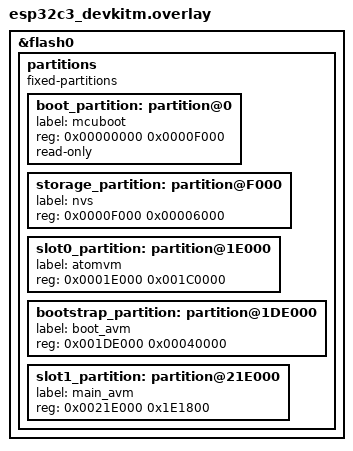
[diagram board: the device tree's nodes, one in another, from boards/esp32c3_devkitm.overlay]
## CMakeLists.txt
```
#
# This file is part of AtomVM.
#
# Copyright 2023 Winford (Uncle Grumpy) <winford@object.stream>
#
# Licensed under the Apache License, Version 2.0 (the "License");
# you may not use this file except in compliance with the License.
# You may obtain a copy of the License at
#
#    http://www.apache.org/licenses/LICENSE-2.0
#
# Unless required by applicable law or agreed to in writing, software
# distributed under the License is distributed on an "AS IS" BASIS,
# WITHOUT WARRANTIES OR CONDITIONS OF ANY KIND, either express or implied.
# See the License for the specific language governing permissions and
# limitations under the License.
#
# SPDX-License-Identifier: Apache-2.0 OR LGPL-2.1-or-later
#

cmake_minimum_required (VERSION 3.13)
set(CMAKE_C_STANDARD_REQUIRED YES)
set(CMAKE_CXX_STANDARD_REQUIRED YES)
# Enforce to disable any compiler-specific extensions
set(CMAKE_C_EXTENSIONS NO)
set(CMAKE_CXX_EXTENSIONS NO)
list(APPEND CMAKE_MODULE_PATH "${CMAKE_CURRENT_SOURCE_DIR}/../../../CMakeModules")

if (NOT BOARD)
    message(FATAL_ERROR "No BOARD specified for device config generator")
endif ()

find_package(Zephyr REQUIRED HINTS $ENV{ZEPHYR_BASE})
set(AVM_ZEPHYR_BUILD ON)
set_property(GLOBAL PROPERTY AVM_ZEPHYR_BUILD ON)
set_property(TARGET app PROPERTY CSTD 11)
set_property(GLOBAL PROPERTY CSTD c11)

project(AtomVM LANGUAGES C)

set(AVM_PEDANTIC_WARNINGS OFF)

if (CONFIG_ATOMVM_DISABLE_SMP)
    set(CMAKE_C_FLAGS "${CMAKE_C_FLAGS} -DAVM_NO_SMP")
endif()

if (CONFIG_AVM_CREATE_STACKTRACES)
    set(AVM_CREATE_STACKTRACES on)
endif()

if (CONFIG_AVM_USE_32BIT_FLOAT)
    set(AVM_USE_32BIT_FLOAT on)
endif()

if (CONFIG_AVM_VERBOSE_ABORT)
    set(AVM_VERBOSE_ABORT on)
endif()

if (CONFIG_REBOOT_ON_NOT_OK)
    add_compile_definitions(CONFIG_REBOOT_ON_NOT_OK)
endif()

    # Configure logging
if (CONFIG_AVM_LOG_DISABLE)
    add_compile_definitions(AVM_LOG_DISABLE)
elseif (CONFIG_AVM_LOG_LEVEL_MAX)
    set(AVM_LOG_LEVEL_MAX ${CONFIG_AVM_LOG_LEVEL_MAX} CACHE STRING "AtomVM max log level")
elseif (CONFIG_LOG_NONE)
    add_compile_definitions(AVM_LOG_DISABLE)
elseif (CONFIG_LOG_ERROR)
    set(AVM_LOG_LEVEL_MAX LOG_ERROR CACHE STRING "AtomVM max log level")
elseif (CONFIG_LOG_WARN)
    set(AVM_LOG_LEVEL_MAX LOG_WARN CACHE STRING "AtomVM max log level")
elseif (CONFIG_LOG_INFO)
    set(AVM_LOG_LEVEL_MAX LOG_INFO CACHE STRING "AtomVM max log level")
elseif (CONFIG_LOG_DEBUG)
    set(AVM_LOG_LEVEL_MAX LOG_DEBUG CACHE STRING "AtomVM max log level")
else()
    set(AVM_LOG_LEVEL_MAX LOG_INFO CACHE STRING "AtomVM max log level")
endif()
if (AVM_LOG_LEVEL_MAX)
    set_property(CACHE AVM_LOG_LEVEL_MAX PROPERTY STRINGS LOG_NONE LOG_ERROR LOG_WARN LOG_INFO LOG_DEBUG)
    add_compile_definitions(AVM_LOG_LEVEL_MAX=${AVM_LOG_LEVEL_MAX})
endif()
if (CONFIG_AVM_ENABLE_LOG_COLOR)
    add_compile_definitions(ENABLE_LOG_COLOR)
endif()
if (CONFIG_AVM_ENABLE_LOG_LINES)
    add_compile_definitions(ENABLE_LOG_LINE_INFO)
endif()

set(
    PLATFORM_LIB_SUFFIX
    ${CMAKE_SYSTEM_NAME}-${CMAKE_SYSTEM_PROCESSOR}
)

# Specify output executable
target_sources(app PRIVATE src/main.c)
target_include_directories(app PRIVATE
    ${CMAKE_CURRENT_SOURCE_DIR}/src/lib
    ${CMAKE_CURRENT_BINARY_DIR}/libAtomVM
    ${CMAKE_CURRENT_SOURCE_DIR}/../../libAtomVM
    ${CMAKE_BINARY_DIR}/zephyr/include/generated
)

add_subdirectory(${CMAKE_CURRENT_SOURCE_DIR}/../../libAtomVM libAtomVM)
target_link_libraries(app PUBLIC libAtomVM)

add_subdirectory(src/lib)
target_link_libraries(app PUBLIC libAtomVM${PLATFORM_LIB_SUFFIX})

if(CMAKE_COMPILER_IS_GNUCC)
    target_compile_options(app PUBLIC -Wall -Wextra -ggdb)
endif()

message("----------------------------------------")
message(STATUS "System name  : ${CMAKE_SYSTEM_NAME}")
message(STATUS "Board        : ${BOARD}")
message(STATUS "Processor    : ${CMAKE_SYSTEM_PROCESSOR}")
message(STATUS "CPU cores    : ${CONFIG_MP_MAX_NUM_CPUS}")
message("--------Device Configuration Info-------")
message(STATUS "Clock Hz     : ${CONFIG_SYS_CLOCK_HW_CYCLES_PER_SEC}")
if (CONFIG_FLASH_SIZE)
message(STATUS "Flash Size   : ${CONFIG_FLASH_SIZE} KiB")
endif()
message("---------Build Configuration------------")
message(STATUS "Zephyr build : ${AVM_ZEPHYR_BUILD}")
message(STATUS "Log Level    : ${AVM_LOG_LEVEL_MAX}")
message(STATUS "Color Logs   : ${CONFIG_AVM_ENABLE_LOG_COLOR}")
message(STATUS "Log all lines: ${CONFIG_AVM_ENABLE_LOG_LINES}")
message(STATUS "Stactraces   : ${CONFIG_AVM_CREATE_STACKTRACES}")
message(STATUS "Verbose abort: ${CONFIG_AVM_VERBOSE_ABORT}")
message(STATUS "Error Reboot : ${CONFIG_REBOOT_ON_NOT_OK}")
message(STATUS "SMP disabled : ${CONFIG_ATOMVM_DISABLE_SMP}")
message(STATUS "32-Bit Floats: ${AVM_USE_32BIT_FLOAT}")
message(STATUS "Sim Flash    : ${CONFIG_FLASH_SIMULATOR}")
```

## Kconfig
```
#
# This file is part of AtomVM.
#
# Copyright 2023 Adolfo E. García 
# Copyright 2023 Winford (Uncle Grumpy) <winford@object.stream>
#
# Licensed under the Apache License, Version 2.0 (the "License");
# you may not use this file except in compliance with the License.
# You may obtain a copy of the License at
#
#    http://www.apache.org/licenses/LICENSE-2.0
#
# Unless required by applicable law or agreed to in writing, software
# distributed under the License is distributed on an "AS IS" BASIS,
# WITHOUT WARRANTIES OR CONDITIONS OF ANY KIND, either express or implied.
# See the License for the specific language governing permissions and
# limitations under the License.
#
# SPDX-License-Identifier: Apache-2.0 OR LGPL-2.1-or-later

rsource "$ZEPHYR_BASE/Kconfig"

menu "AtomVM"
config ATOMVM
    bool "AtomVM"
    default y
    help
        Enables the AtomVM Module
    select CBPRINTF_PACKAGE_LONGDOUBLE
    select CONSOLE_SUBSYS
    select EMIT_ALL_SYSCALLS
    select FLASH
    select FLASH_MAP
    select FLASH_MAP_CUSTOM
    select FLASH_MAP_LABELS
    select HAVE_CLOCK_SETTIME
    select OUTPUT_PRINT_MEMORY_USAGE
    select REQUIRES_FLOAT_PRINTF
    select RTC
    select STACK_USAGE
    select UTF8

    if ATOMVM
    rsource "src/Kconfig"
    endif

if ATOMVM

module = ATOMVM
module-str = AtomVM

endif

endmenu
```

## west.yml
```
# Copyright (c) 2021 Nordic Semiconductor ASA
# SPDX-License-Identifier: Apache-2.0

manifest:
  remotes:
    - name: zephyrproject-rtos
      url-base: https://github.com/zephyrproject-rtos
  defaults:
    remote: zephyrproject-rtos
  projects:
    - name: zephyr
      remote: zephyrproject-rtos
      revision: v3.5.0
      import:
        # By using name-allowlist we can clone only the modules that are
        # strictly needed by the application.
        name-allowlist:
          - cmsis          # required by the ARM port
          - stm32          # required by STM32 boards
          - native_sim_64  # 64-bit native
          - qemu_x86_64    # QEMU 64-bit virtual machine
  self:
    path: .
```

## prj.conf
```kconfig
#
# This file is part of AtomVM.
#
# Copyright 2023 Winford (Uncle Grumpy) <winford@object.stream>
#
# Licensed under the Apache License, Version 2.0 (the "License");
# you may not use this file except in compliance with the License.
# You may obtain a copy of the License at
#
#    http://www.apache.org/licenses/LICENSE-2.0
#
# Unless required by applicable law or agreed to in writing, software
# distributed under the License is distributed on an "AS IS" BASIS,
# WITHOUT WARRANTIES OR CONDITIONS OF ANY KIND, either express or implied.
# See the License for the specific language governing permissions and
# limitations under the License.
#
# SPDX-License-Identifier: Apache-2.0 OR LGPL-2.1-or-later
#

CONFIG_KERNEL_BIN_NAME="AtomVM"
CONFIG_RUNTIME_ERROR_CHECKS=y
CONFIG_FORTIFY_SOURCE_RUN_TIME=y
CONFIG_FLASH=y
CONFIG_SPI=y


CONFIG_STDOUT_CONSOLE=y
CONFIG_CONSOLE_SUBSYS=y
CONFIG_POSIX_API=y
CONFIG_APP_LINK_WITH_POSIX_SUBSYS=y
CONFIG_POSIX_CLOCK=y
CONFIG_FPU=y
CONFIG_FP_HARDABI=y
CONFIG_GPIO=y
CONFIG_PINCTRL_DYNAMIC=y
CONFIG_DYNAMIC_INTERRUPTS=y
CONFIG_RESET=y
CONFIG_REBOOT=y
CONFIG_PICOLIBC=y


# CONFIG_DEBUG_OPTIMIZATIONS=y

CONFIG_APPLICATION_DEFINED_SYSCALL=y
CONFIG_EMIT_ALL_SYSCALLS=y
```

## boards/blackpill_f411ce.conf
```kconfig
#
# This file is part of AtomVM.
#
# Copyright 2023 Winford (Uncle Grumpy) <winford@object.stream>
#
# Licensed under the Apache License, Version 2.0 (the "License");
# you may not use this file except in compliance with the License.
# You may obtain a copy of the License at
#
#    http://www.apache.org/licenses/LICENSE-2.0
#
# Unless required by applicable law or agreed to in writing, software
# distributed under the License is distributed on an "AS IS" BASIS,
# WITHOUT WARRANTIES OR CONDITIONS OF ANY KIND, either express or implied.
# See the License for the specific language governing permissions and
# limitations under the License.
#
# SPDX-License-Identifier: Apache-2.0 OR LGPL-2.1-or-later
#

CONFIG_STDOUT_CONSOLE=y
CONFIG_POSIX_API=y
CONFIG_POSIX_CLOCK=y
```

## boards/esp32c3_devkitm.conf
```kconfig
#
# This file is part of AtomVM.
#
# Copyright 2023 Winford (Uncle Grumpy) <winford@object.stream>
#
# Licensed under the Apache License, Version 2.0 (the "License");
# you may not use this file except in compliance with the License.
# You may obtain a copy of the License at
#
#    http://www.apache.org/licenses/LICENSE-2.0
#
# Unless required by applicable law or agreed to in writing, software
# distributed under the License is distributed on an "AS IS" BASIS,
# WITHOUT WARRANTIES OR CONDITIONS OF ANY KIND, either express or implied.
# See the License for the specific language governing permissions and
# limitations under the License.
#
# SPDX-License-Identifier: Apache-2.0 OR LGPL-2.1-or-later
#

CONFIG_FPU=n
CONFIG_POSIX_CLOCK=y
```

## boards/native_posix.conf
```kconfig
#
# This file is part of AtomVM.
#
# Copyright 2023 Winford (Uncle Grumpy) <winford@object.stream>
#
# Licensed under the Apache License, Version 2.0 (the "License");
# you may not use this file except in compliance with the License.
# You may obtain a copy of the License at
#
#    http://www.apache.org/licenses/LICENSE-2.0
#
# Unless required by applicable law or agreed to in writing, software
# distributed under the License is distributed on an "AS IS" BASIS,
# WITHOUT WARRANTIES OR CONDITIONS OF ANY KIND, either express or implied.
# See the License for the specific language governing permissions and
# limitations under the License.
#
# SPDX-License-Identifier: Apache-2.0 OR LGPL-2.1-or-later
#

CONFIG_KERNEL_BIN_NAME="AtomVM"
CONFIG_ATOMVM_DISABLE_SMP=y
CONFIG_FLASH_SIMULATOR=y

CONFIG_RESET=n
CONFIG_REBOOT=n

CONFIG_RUNTIME_ERROR_CHECKS=y
CONFIG_FORTIFY_SOURCE_RUN_TIME=y
CONFIG_DEBUG_OPTIMIZATIONS=y
```

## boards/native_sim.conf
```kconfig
#
# This file is part of AtomVM.
#
# Copyright 2023 Winford (Uncle Grumpy) <winford@object.stream>
#
# Licensed under the Apache License, Version 2.0 (the "License");
# you may not use this file except in compliance with the License.
# You may obtain a copy of the License at
#
#    http://www.apache.org/licenses/LICENSE-2.0
#
# Unless required by applicable law or agreed to in writing, software
# distributed under the License is distributed on an "AS IS" BASIS,
# WITHOUT WARRANTIES OR CONDITIONS OF ANY KIND, either express or implied.
# See the License for the specific language governing permissions and
# limitations under the License.
#
# SPDX-License-Identifier: Apache-2.0 OR LGPL-2.1-or-later
#

CONFIG_KERNEL_BIN_NAME="AtomVM"
CONFIG_ATOMVM_DISABLE_SMP=y
CONFIG_FLASH_SIMULATOR=y

CONFIG_RESET=n
CONFIG_REBOOT=n
CONFIG_RUNTIME_ERROR_CHECKS=y
CONFIG_FORTIFY_SOURCE_RUN_TIME=y
CONFIG_DEBUG_OPTIMIZATIONS=y
```

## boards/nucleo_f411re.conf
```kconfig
#
# This file is part of AtomVM.
#
# Copyright 2023 Winford (Uncle Grumpy) <winford@object.stream>
#
# Licensed under the Apache License, Version 2.0 (the "License");
# you may not use this file except in compliance with the License.
# You may obtain a copy of the License at
#
#    http://www.apache.org/licenses/LICENSE-2.0
#
# Unless required by applicable law or agreed to in writing, software
# distributed under the License is distributed on an "AS IS" BASIS,
# WITHOUT WARRANTIES OR CONDITIONS OF ANY KIND, either express or implied.
# See the License for the specific language governing permissions and
# limitations under the License.
#
# SPDX-License-Identifier: Apache-2.0 OR LGPL-2.1-or-later
#

AVM_DISABLE_SMP=y
CONFIG_STDOUT_CONSOLE=y
CONFIG_POSIX_CLOCK=y
```

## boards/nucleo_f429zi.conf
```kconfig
#
# This file is part of AtomVM.
#
# Copyright 2023 Winford (Uncle Grumpy) <winford@object.stream>
#
# Licensed under the Apache License, Version 2.0 (the "License");
# you may not use this file except in compliance with the License.
# You may obtain a copy of the License at
#
#    http://www.apache.org/licenses/LICENSE-2.0
#
# Unless required by applicable law or agreed to in writing, software
# distributed under the License is distributed on an "AS IS" BASIS,
# WITHOUT WARRANTIES OR CONDITIONS OF ANY KIND, either express or implied.
# See the License for the specific language governing permissions and
# limitations under the License.
#
# SPDX-License-Identifier: Apache-2.0 OR LGPL-2.1-or-later
#

CONFIG_SYS_CLOCK_HW_CYCLES_PER_SEC=180000000
CONFIG_STDOUT_CONSOLE=y
CONFIG_POSIX_API=y
CONFIG_POSIX_CLOCK=y
```

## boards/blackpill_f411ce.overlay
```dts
/*
* This file is part of AtomVM.
*
* Copyright 2023 Winford (Uncle Grumpy) <winford@object.stream>
*
* Licensed under the Apache License, Version 2.0 (the "License");
* you may not use this file except in compliance with the License.
* You may obtain a copy of the License at
*
*    http://www.apache.org/licenses/LICENSE-2.0
*
* Unless required by applicable law or agreed to in writing, software
* distributed under the License is distributed on an "AS IS" BASIS,
* WITHOUT WARRANTIES OR CONDITIONS OF ANY KIND, either express or implied.
* See the License for the specific language governing permissions and
* limitations under the License.
*
* SPDX-License-Identifier: Apache-2.0 OR LGPL-2.1-or-later
*/

&flash0 {

        partitions {
                compatible = "fixed-partitions";
                #address-cells = <1>;
                #size-cells = <1>;

                vm_partition: partition@0 {
                        label = "atomvm";
                        reg = <0x00000000 DT_SIZE_K(384)>;
                };
                app_partition: partition@60000 {
                        label = "main_avm";
                        reg = <0x00060000 DT_SIZE_K(128)>;
                };
        };
};
```

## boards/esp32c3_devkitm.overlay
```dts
/*
* This file is part of AtomVM.
*
* Copyright 2023 Winford (Uncle Grumpy) <winford@object.stream>
*
* Licensed under the Apache License, Version 2.0 (the "License");
* you may not use this file except in compliance with the License.
* You may obtain a copy of the License at
*
*    http://www.apache.org/licenses/LICENSE-2.0
*
* Unless required by applicable law or agreed to in writing, software
* distributed under the License is distributed on an "AS IS" BASIS,
* WITHOUT WARRANTIES OR CONDITIONS OF ANY KIND, either express or implied.
* See the License for the specific language governing permissions and
* limitations under the License.
*
* SPDX-License-Identifier: Apache-2.0 OR LGPL-2.1-or-later
*/

&flash0 {
        status = "okay";
        partitions {
                compatible = "fixed-partitions";
                #address-cells = <1>;
                #size-cells = <1>;

                /* Reserve 60kB for the bootloader */
                boot_partition: partition@0 {
                        label = "mcuboot";
                        reg = <0x00000000 0x0000F000>;
                        read-only;
                };

                /* Reserve 24kB for NVS in slot 0 */
                storage_partition: partition@F000 {
                        label = "nvs";
                        reg = <0x0000F000 0x00006000>;
                };

                /* Reserve 1792kB for AtomVM in slot 1 */
                slot0_partition: partition@1E000 {
                        label = "atomvm";
                        reg = <0x0001E000 0x001C0000>;
                };

                /* Reserve 256kB for the boot_avm bootstrap partition */
                bootstrap_partition: partition@1DE000 {
                           label = "boot_avm";
                           reg = <0x001DE000 0x00040000>;
                };

                /* Remaining ~2M for the main_avm application partition */
                slot1_partition: partition@21E000 {
                        label = "main_avm";
                        reg = <0x0021E000 0x1E1800>;
                };
        };
};
```

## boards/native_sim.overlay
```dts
/*
* This file is part of AtomVM.
*
* Copyright 2023 Winford (Uncle Grumpy) <winford@object.stream>
*
* Licensed under the Apache License, Version 2.0 (the "License");
* you may not use this file except in compliance with the License.
* You may obtain a copy of the License at
*
*    http://www.apache.org/licenses/LICENSE-2.0
*
* Unless required by applicable law or agreed to in writing, software
* distributed under the License is distributed on an "AS IS" BASIS,
* WITHOUT WARRANTIES OR CONDITIONS OF ANY KIND, either express or implied.
* See the License for the specific language governing permissions and
* limitations under the License.
*
* SPDX-License-Identifier: Apache-2.0 OR LGPL-2.1-or-later
*/

flashcontroller0: flash-controller@0 {
        compatible = "zephyr,sim-flash";
        reg = <0x00000000 DT_SIZE_K(2048)>;

        #address-cells = <1>;
        #size-cells = <1>;
        erase-value = <0xff>;

        flash0: flash@0 {
                status = "okay";
                compatible = "soc-nv-flash";
                erase-block-size = <4096>;
                write-block-size = <1>;
                reg = <0x00000000 DT_SIZE_K(2048)>;

                partitions {
                        compatible = "fixed-partitions";
                        #address-cells = <1>;
                        #size-cells = <1>;

                        /* 48kB bootloader */
                        boot_partition: partition@0 {
                                label = "mcuboot";
                                reg = <0x00000000 0x0000C000>;
                        };

                        /* 24kB NVS */
                        nvs_partition: partition@c000 {
                                label = "nvs";
                                reg = <0x000C000 0x00004000>;
                        };
                        /* Remaining 1960kB for the main_avm application partition */
                        app_partition: partition@10000 {
                                label = "main_avm";
                                reg = <0x00010000 0x001EA000>;
                        };

                };
        };
};
```

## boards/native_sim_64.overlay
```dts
/*
* This file is part of AtomVM.
*
* Copyright 2023 Winford (Uncle Grumpy) <winford@object.stream>
*
* Licensed under the Apache License, Version 2.0 (the "License");
* you may not use this file except in compliance with the License.
* You may obtain a copy of the License at
*
*    http://www.apache.org/licenses/LICENSE-2.0
*
* Unless required by applicable law or agreed to in writing, software
* distributed under the License is distributed on an "AS IS" BASIS,
* WITHOUT WARRANTIES OR CONDITIONS OF ANY KIND, either express or implied.
* See the License for the specific language governing permissions and
* limitations under the License.
*
* SPDX-License-Identifier: Apache-2.0 OR LGPL-2.1-or-later
*/

&flash0 {
        status = "okay";
        compatible = "soc-nv-flash";
        erase-block-size = <4096>;
        write-block-size = <1>;
        reg = <0x00000000 DT_SIZE_K(2048)>;

        partitions {
                compatible = "fixed-partitions";
                #address-cells = <1>;
                #size-cells = <1>;

                /* 24kB NVS */
                nvs_partition: partition@0 {
                        label = "nvs";
                        reg = <0x0000000 0x00004000>;
                };
                /* Remaining 1960kB for the main_avm application partition */
                app_partition: partition@4000 {
                        label = "main_avm";
                        reg = <0x00004000 0x001F4000>;
                };

        };
};
```

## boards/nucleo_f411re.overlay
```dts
/*
* This file is part of AtomVM.
*
* Copyright 2023 Winford (Uncle Grumpy) <winford@object.stream>
*
* Licensed under the Apache License, Version 2.0 (the "License");
* you may not use this file except in compliance with the License.
* You may obtain a copy of the License at
*
*    http://www.apache.org/licenses/LICENSE-2.0
*
* Unless required by applicable law or agreed to in writing, software
* distributed under the License is distributed on an "AS IS" BASIS,
* WITHOUT WARRANTIES OR CONDITIONS OF ANY KIND, either express or implied.
* See the License for the specific language governing permissions and
* limitations under the License.
*
* SPDX-License-Identifier: Apache-2.0 OR LGPL-2.1-or-later
*/

&flash0 {

        partitions {
                compatible = "fixed-partitions";
                #address-cells = <1>;
                #size-cells = <1>;

                slot0_partition: partition@0 {
                        label = "atomvm";
                        reg = <0x00000000 DT_SIZE_K(384)>;
                };
                slot1_partition: partition@60000 {
                        label = "main_avm";
                        reg = <0x00060000 DT_SIZE_K(128)>;
                };
        };
};
```

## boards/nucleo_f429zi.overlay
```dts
/*
* This file is part of AtomVM.
*
* Copyright 2023 Winford (Uncle Grumpy) <winford@object.stream>
*
* Licensed under the Apache License, Version 2.0 (the "License");
* you may not use this file except in compliance with the License.
* You may obtain a copy of the License at
*
*    http://www.apache.org/licenses/LICENSE-2.0
*
* Unless required by applicable law or agreed to in writing, software
* distributed under the License is distributed on an "AS IS" BASIS,
* WITHOUT WARRANTIES OR CONDITIONS OF ANY KIND, either express or implied.
* See the License for the specific language governing permissions and
* limitations under the License.
*
* SPDX-License-Identifier: Apache-2.0 OR LGPL-2.1-or-later
*/

&flash0 {

        partitions {
                compatible = "fixed-partitions";
                #address-cells = <1>;
                #size-cells = <1>;

                vm_partition: partition@0 {
                        label = "atomvm";
                        reg = <0x00000000 DT_SIZE_K(512)>;
                };
                app_partition: partition@80000 {
                        label = "main_avm";
                        reg = <0x00080000 DT_SIZE_K(1536)>;
                };
        };
};
```

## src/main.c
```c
/*
 * This file is part of AtomVM.
 *
 * Copyright 2023 Winford (Uncle Grumpy) <winford@object.stream>
 * Copyright 2017-2023 Davide Bettio <davide@uninstall.it>
 *
 * Licensed under the Apache License, Version 2.0 (the "License");
 * you may not use this file except in compliance with the License.
 * You may obtain a copy of the License at
 *
 *    http://www.apache.org/licenses/LICENSE-2.0
 *
 * Unless required by applicable law or agreed to in writing, software
 * distributed under the License is distributed on an "AS IS" BASIS,
 * WITHOUT WARRANTIES OR CONDITIONS OF ANY KIND, either express or implied.
 * See the License for the specific language governing permissions and
 * limitations under the License.
 *
 * SPDX-License-Identifier: Apache-2.0 OR LGPL-2.1-or-later
 */

#include <errno.h>
#include <signal.h>
#include <stdio.h>
#include <unistd.h>

#include <autoconf.h>
#include <devicetree_generated.h>
#include <zephyr/drivers/flash.h>

#include <zephyr/kernel.h>
#include <zephyr/storage/flash_map.h>
#include <zephyr/sys/reboot.h>

#include <avm_version.h>
#include <avmpack.h>
#include <context.h>
#include <defaultatoms.h>
#include <globalcontext.h>
#include <module.h>
#include <utils.h>

// #include "lib/avm_devcfg.h"
#include "lib/avm_log.h"
#include "lib/zephyros_sys.h"

#define TAG "AtomVM"
#define AVM_ADDRESS FIXED_PARTITION_OFFSET(app_partition)
#define APP_MAX_SIZE FIXED_PARTITION_SIZE(app_partition)

#define ATOMVM_BANNER                                                   \
    "\n"                                                                \
    "    ###########################################################\n" \
    "\n"                                                                \
    "       ###    ########  #######  ##     ## ##     ## ##     ## \n" \
    "      ## ##      ##    ##     ## ###   ### ##     ## ###   ### \n" \
    "     ##   ##     ##    ##     ## #### #### ##     ## #### #### \n" \
    "    ##     ##    ##    ##     ## ## ### ## ##     ## ## ### ## \n" \
    "    #########    ##    ##     ## ##     ##  ##   ##  ##     ## \n" \
    "    ##     ##    ##    ##     ## ##     ##   ## ##   ##     ## \n" \
    "    ##     ##    ##     #######  ##     ##    ###    ##     ## \n" \
    "\n"                                                                \
    "    ###########################################################\n" \
    "\n"

int main()
{

    GlobalContext *glb = globalcontext_new();

    printk("%s", ATOMVM_BANNER);
    AVM_LOGI(TAG, "Starting AtomVM revision %s", ATOMVM_VERSION);

    const void *flashed_avm = (void *) AVM_ADDRESS;
    uint32_t size = APP_MAX_SIZE;
    AVM_LOGD(TAG, "Maximum application size: %lu KiB", (size / 1024));

    uint32_t startup_beam_size;
    const void *startup_beam;
    const char *startup_module_name;

    if (!avmpack_is_valid(flashed_avm, size) || !avmpack_find_section_by_flag(flashed_avm, BEAM_START_FLAG, &startup_beam, &startup_beam_size, &startup_module_name)) {
        AVM_LOGE(TAG, "Invalid AVM Pack");
        AVM_ABORT();
    }
    AVM_LOGD(TAG, "Booting file mapped at: %p, size: %lu", flashed_avm, startup_beam_size);
    AVM_LOGI(TAG, "Application size: %lu B, free flash space: %lu KiB", startup_beam_size, ((size - startup_beam_size) / 1024));

    struct ConstAVMPack *avmpack_data = malloc(sizeof(struct ConstAVMPack));
    if (IS_NULL_PTR(avmpack_data)) {
        AVM_LOGE(TAG, "Memory error: Cannot allocate AVMPackData.");
        AVM_ABORT();
    }
    avmpack_data_init(&avmpack_data->base, &const_avm_pack_info);
    avmpack_data->base.data = flashed_avm;
    avmpack_data->base.in_use = true;
    synclist_append(&glb->avmpack_data, &avmpack_data->base.avmpack_head);

    Module *mod = module_new_from_iff_binary(glb, startup_beam, startup_beam_size);
    globalcontext_insert_module(glb, mod);
    Context *ctx = context_new(glb);
    ctx->leader = 1;

    port_driver_init_all(glb);
    nif_collection_init_all(glb);

    printk("Starting: %s...\n", startup_module_name);
    printk("---\n");

    context_execute_loop(ctx, mod, "start", 0);

    term ret_value = ctx->x[0];
    char *ret_atom_string = interop_atom_to_string(ctx, ret_value);
    if (ret_atom_string != NULL) {
        AVM_LOGI(TAG, "Exited with return: %s", ret_atom_string);
    } else {
        AVM_LOGI(TAG, "Exited with return value: %lx", (long) term_to_int32(ret_value));
    }
    free(ret_atom_string);

    bool reboot_on_not_ok =
#if defined(CONFIG_REBOOT_ON_NOT_OK)
        CONFIG_REBOOT_ON_NOT_OK ? true : false;
#else
        false;
#endif
    if (reboot_on_not_ok && ret_value != OK_ATOM) {
        AVM_LOGE(TAG, "AtomVM application terminated with non-ok return value.  Rebooting ...");
        sys_reboot(SYS_REBOOT_COLD);
    } else {
        AVM_LOGI(TAG, "AtomVM application terminated.  Going to sleep forever ...");
        while (1) {
            ;
        }
    }
    return 0;
}
```
